# K1921VK035 register map
Vendor: NIIET; Series: K1921VKx; File version: 2.10
CPU: CM4 r0p1, little endian, MPU, FPU, 3 interrupt priority bits
Registers are 32-bit, read-write, reset 0x0 unless marked. A register's access mark holds for its fields unless they carry their own. Offsets are from the block's base; [hi:lo] are bit positions; lines under a group give offsets from that group; {n}, {i} and the like mark numbered series.

## CAN — CAN controller registers
Base 0x40020000
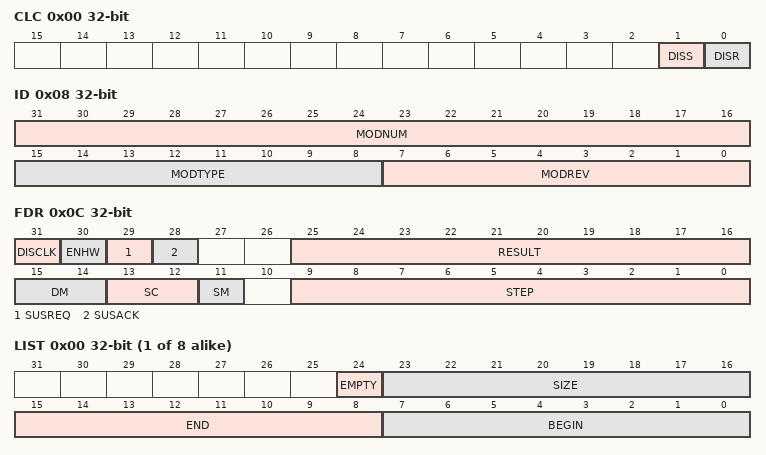
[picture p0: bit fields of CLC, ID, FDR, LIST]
0x00 CLC — CAN Clock Control Register
  [1] DISS ro — Module Disable Status Bit
  [0] DISR — Module Disable Request bit
0x08 ID — Module Identification Register
  [31:16] MODNUM ro — Module Number Value
  [15:8] MODTYPE ro — Module type
  [7:0] MODREV — Module Revision Number
0x0C FDR — Fractional Divider Register
  [31] DISCLK — Disable Clock
  [30] ENHW — Enable Hardware Clock Control
  [29] SUSREQ ro — Suspend Mode Request
  [28] SUSACK ro — Suspend Mode Acknowledge
  [25:16] RESULT ro — Result Value
  [15:14] DM
    0=Disable (counter disabled); 1=NormalMode (normal operation mode); 2=DividerMode (divider operation mode)
  [13:12] SC — Suspend Control
  [11] SM — Suspend Mode
  [9:0] STEP — Step Value
{0x100+4i} LIST[{i}] (i=0..7) group
  0x00 LIST ro — List Register0
    [24] EMPTY — List Empty Indication
    [23:16] SIZE — List Size
    [15:8] END — List End
    [7:0] BEGIN — List Begin
{0x140+4i} MSPND[{i}] (i=0..3) group
  0x00 MSPND — Message Pending Register0
    [31:0] PND — Message Pending
{0x180+4i} MSID[{i}] (i=0..3) group
  0x00 MSID ro — Message Index Register0
    [7:0] INDEX — Message Pending Index
0x1C0 MSIMASK — Message Index Mask Register
  [31:0] IM — Message Index Mask
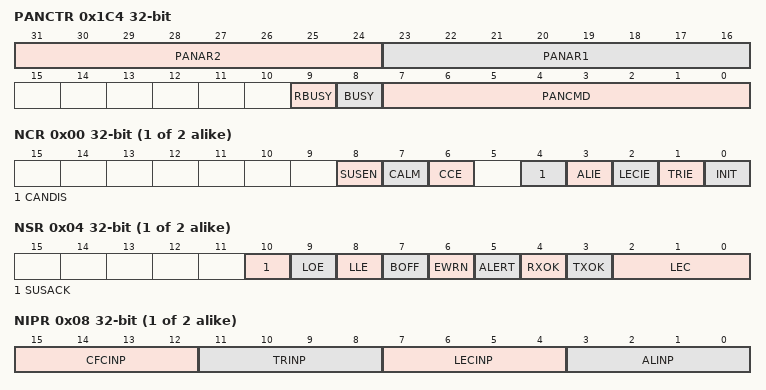
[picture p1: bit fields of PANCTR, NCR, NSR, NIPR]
0x1C4 PANCTR — Panel Control Register
  [31:24] PANAR2 — Panel argument 2
  [23:16] PANAR1 — Panel argument 1
  [9] RBUSY ro — Result Busy Flag
  [8] BUSY ro — Panel Busy Flag
  [7:0] PANCMD — Panel Command
0x1C8 MCR
  [15:12] MPSEL — Message Pending Selector
0x1CC MITR wo — Module Interrupt Trigger Register
  [15:0] IT — Interrupt Trigger
{0x200+0x100*i} Node[{i}] (i=0..1) group
  0x00 NCR — Node control register0
    [8] SUSEN — Suspend Enable
    [7] CALM — CAN Analyzer Mode
    [6] CCE — Configuration Change Enable
    [4] CANDIS — CAN Disable
    [3] ALIE — Alert Interrupt Enable
    [2] LECIE — LEC Indicated Error Interrupt Enable
    [1] TRIE — Transfer Interrupt Enable
    [0] INIT — Node Initialization
  0x04 NSR — Node Status Register0
    [10] SUSACK ro — Suspend Acknowledge
    [9] LOE — List Object Error
    [8] LLE — List Length Error
    [7] BOFF ro — Bus-Off Status
    [6] EWRN ro — Error Warning Status
    [5] ALERT — Alert Warning
    [4] RXOK — Message Received Successfully
    [3] TXOK — Message Transmitted Successfully
    [2:0] LEC — Last Error Code
      0=no error; 1=stuff error; 2=form error; 3=AckErr (acknowlegment error); 4=bit 1 error; 5=bit 0 error; 6=CRC error; 7=WriteEn (enable hardware write)
  0x08 NIPR — Node Interrupt Pointer Register0
    [15:12] CFCINP — Frame Counter Interrupt Node Pointer
    [11:8] TRINP — Transfer OK Interrupt Node Pointer
    [7:4] LECINP — Last Error Code Interrupt Node Pointer
    [3:0] ALINP — Alert Interrupt Node Pointer
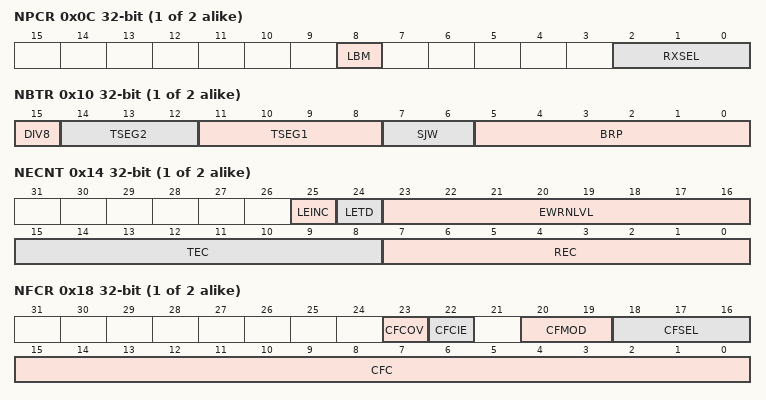
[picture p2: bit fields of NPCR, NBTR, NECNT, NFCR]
  0x0C NPCR — Node Port Control Register0
    [8] LBM — Loop-Back Mode
    [2:0] RXSEL — Receive Select
  0x10 NBTR — Node Bit Timing Register0
    [15] DIV8 — Divide Prescaler Clock by 8
    [14:12] TSEG2 — Time Segment After Sample Point
    [11:8] TSEG1 — Time Segment Before Sample Point
    [7:6] SJW
    [5:0] BRP — Baud Rate Prescaler
  0x14 NECNT — Node Error Counter Register0
    [25] LEINC ro — Last Error Increment
    [24] LETD ro — Last Error Transfer Direction
    [23:16] EWRNLVL — Error Warning Level
    [15:8] TEC — Transmit Error Counter
    [7:0] REC — Receive Error Counter
  0x18 NFCR — Node Frame Counter Register0
    [23] CFCOV — CAN Frame Counter Overflow Flag
    [22] CFCIE — CAN Frame Counter Interrupt Enable
    [20:19] CFMOD — CAN Frame Counter Mode
    [18:16] CFSEL — CAN Frame Count Selection
    [15:0] CFC — CAN Frame Counter
